# DA14681 register map
Vendor: Dialog; Series: DA14681; File version: 1.2
CPU: CM0 r1p0, little endian, MPU, FPU, 3 interrupt priority bits
Registers are 16-bit, read-write, reset 0x0 unless marked. A register's access mark holds for its fields unless they carry their own. Offsets are from the block's base; [hi:lo] are bit positions; <NAME> marks a mode.

## TRNG — TRNG registers
Base 0x50005000
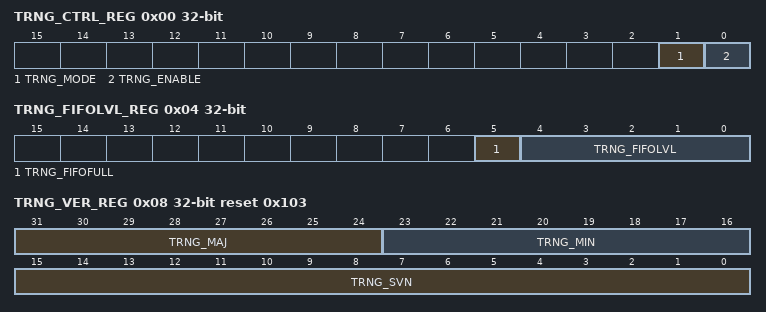
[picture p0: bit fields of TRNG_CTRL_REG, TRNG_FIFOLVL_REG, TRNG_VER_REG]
0x00 TRNG_CTRL_REG 32-bit — TRNG control register
  [1] TRNG_MODE — 0: select the TRNG with asynchronous free running oscillators (default) 1: select the pseudo-random generator with synchronous oscillators (for simulation purpose only)
  [0] TRNG_ENABLE — 0: Disable the TRNG 1: Enable the TRNG this signal is ignored when the FIFO is full
0x04 TRNG_FIFOLVL_REG 32-bit — TRNG FIFO level register
  [5] TRNG_FIFOFULL ro — 1:FIFO full indication. This bit is cleared if the FIFO is read.
  [4:0] TRNG_FIFOLVL ro — Number of 32 bit words of random data in the FIFO (max 31) until the FIFO is full. When it is 0 and TRNG_FIFOFULL is 1, it means the FIFO is full.
0x08 TRNG_VER_REG 32-bit reset 0x103 (reset mask 0x7FFFFFFF) — TRNG Version register
  [31:24] TRNG_MAJ ro — Major version number
  [23:16] TRNG_MIN ro — Minor version number
  [15:0] TRNG_SVN ro — SVN revision number

## WAKEUP — WAKEUP registers
Base 0x50000100
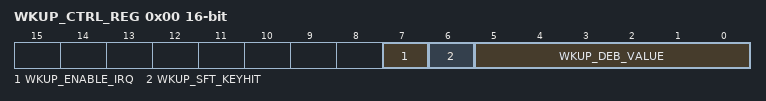
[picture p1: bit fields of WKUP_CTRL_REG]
0x00 WKUP_CTRL_REG — Control register for the wakeup counter
  [7] WKUP_ENABLE_IRQ — 0: no interrupt will be enabled 1: if the event counter reaches the value set by WKUP_COMPARE_REG an IRQ will be generated
  [6] WKUP_SFT_KEYHIT — 0 = no effect 1 = emulate key hit. The event counter will increment by 1 (after debouncing if enabled). First make this bit 0 before any new key hit can be sensed.
  [5:0] WKUP_DEB_VALUE — Keyboard debounce time. If set to 0, no debouncing will be done. Debounce time: N*1 ms. N =1..63 Keyboard Debounce Time
0x02 WKUP_COMPARE_REG — Number of events before wakeup interrupt
  [7:0] COMPARE — The number of events that have to be counted before the wakeup interrupt will be given
0x04 WKUP_RESET_IRQ_REG — Reset wakeup interrupt
  [15:0] WKUP_IRQ_RST wo — writing any value to this register will reset the interrupt. reading always returns 0.
0x06 WKUP_COUNTER_REG — Actual number of events of the wakeup counter
  [7:0] EVENT_VALUE ro — This value represents the number of events that have been counted so far. It will be reset by resetting the interrupt.
0x08 WKUP_RESET_CNTR_REG — Reset the event counter
  [15:0] WKUP_CNTR_RST wo — writing any value to this register will reset the event counter
0x0A WKUP_SELECT_P0_REG — select which inputs from P0 port can trigger wkup counter
  [7:0] WKUP_SELECT_P0 — 0: input P0x is not enabled for wakeup event counter 1: input P0x is enabled for wakeup event counter
0x0C WKUP_SELECT_P1_REG — select which inputs from P1 port can trigger wkup counter
  [7:0] WKUP_SELECT_P1 — 0: input P1x is not enabled for wakeup event counter 1: input P1x is enabled for wakeup event counter
0x0E WKUP_SELECT_P2_REG — select which inputs from P2 port can trigger wkup counter
  [4:0] WKUP_SELECT_P2 — 0: input P2x is not enabled for wakeup event counter 1: input P2x is enabled for wakeup event counter
0x10 WKUP_SELECT_P3_REG — select which inputs from P3 port can trigger wkup counter
  [7:0] WKUP_SELECT_P3 — 0: input P3x is not enabled for wakeup event counter 1: input P3x is enabled for wakeup event counter
0x12 WKUP_SELECT_P4_REG — select which inputs from P4 port can trigger wkup counter
  [7:0] WKUP_SELECT_P4 — 0: input P4x is not enabled for wakeup event counter 1: input P4x is enabled for wakeup event counter
0x14 WKUP_POL_P0_REG — select the sesitivity polarity for each P0 input
  [7:0] WKUP_POL_P0 — 0: enabled input P0x will increment the event counter if that input goes high 1: enabled input P0x will increment the event counter if that input goes low
0x16 WKUP_POL_P1_REG — select the sesitivity polarity for each P1 input
  [7:0] WKUP_POL_P1 — 0: enabled input P1x will increment the event counter if that input goes high 1: enabled input P1x will increment the event counter if that input goes low
0x18 WKUP_POL_P2_REG — select the sesitivity polarity for each P2 input
  [4:0] WKUP_POL_P2 — 0: enabled input P2x will increment the event counter if that input goes high 1: enabled input P2x will increment the event counter if that input goes low
0x1A WKUP_POL_P3_REG — select the sesitivity polarity for each P3 input
  [7:0] WKUP_POL_P3 — 0: enabled input P3x will increment the event counter if that input goes high 1: enabled input P3x will increment the event counter if that input goes low
0x1C WKUP_POL_P4_REG — select the sesitivity polarity for each P3 input
  [7:0] WKUP_POL_P4 — 0: enabled input P4x will increment the event counter if that input goes high 1: enabled input P4x will increment the event counter if that input goes low

## WDOG — WDOG registers
Base 0x50003100
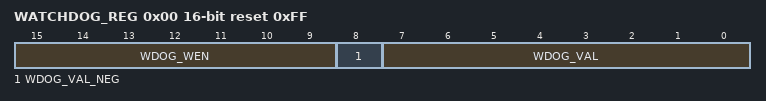
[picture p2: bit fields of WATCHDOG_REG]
0x00 WATCHDOG_REG reset 0xFF — Watchdog timer register.
  [15:9] WDOG_WEN wo — 0000.000 = Write enable for Watchdog timer else Write disable. This filter prevents unintentional presetting the watchdog with a SW run-away.
  [8] WDOG_VAL_NEG — 0 = Watchdog timer value is positive. 1 = Watchdog timer value is negative.
  [7:0] WDOG_VAL — Write: Watchdog timer reload value. Note that all bits 15-9 must be 0 to reload this register. Read: Actual Watchdog timer value. Decremented by 1 every 10.24 msec. Bit 8 indicates a negative counter value. 2, 1, 0, 1FF16, 1FE16 etc. An NMI or WDOG (SYS) reset is generated under the following conditions: If WATCHDOG_CTRL_REG[NMI_RST] = 0 then If WDOG_VAL = 0 -> NMI (Non Maskable Interrupt) if WDOG_VAL = 1F016 -> WDOG reset -> reload FF16 If WATCHDOG_CTRL_REG[NMI_RST] = 1 then if WDOG_VAL <= 0 -> WDOG reset -> reload FF16
0x02 WATCHDOG_CTRL_REG — Watchdog control register.
  [0] NMI_RST — 0 = Watchdog timer generates NMI at value 0, and WDOG (SYS) reset at <=-16. Timer can be frozen /resumed using SET_FREEZE_REG[FRZ_WDOG]/ RESET_FREEZE_REG[FRZ_WDOG]. 1 = Watchdog timer generates a WDOG (SYS) reset at value 0 and can not be frozen by Software. Note that this bit can only be set to 1 by SW and only be reset with a WDOG (SYS) reset or SW reset. The watchdog is always frozen when the Cortex-M0 is halted in DEBUG State.
